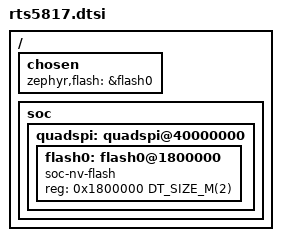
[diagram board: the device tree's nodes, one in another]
/*
 * Copyright (c) 2025 Realtek Semiconductor, Inc.
 * SPDX-License-Identifier: Apache-2.0
 */

#include <realtek/fingerprint/rts5817/rts5817_base.dtsi>

/ {
	chosen {
		zephyr,flash = &flash0;
	};

	soc {
		quadspi: quadspi@40000000 {
			flash0: flash0@1800000 {
				compatible = "soc-nv-flash";
				reg = <0x1800000 DT_SIZE_M(2)>;
				#address-cells = <1>;
				#size-cells = <1>;
				ranges = <0x0 0x1800000 DT_SIZE_M(2)>;
			};
		};
	};
};
